# CM4 register map
CPU: CM4 r0p1, selectable endian, MPU, FPU, 4 interrupt priority bits
Registers are 32-bit, read-write, reset 0x0 unless marked. A register's access mark holds for its fields unless they carry their own. Offsets are from the block's base; [hi:lo] are bit positions.

## FP — Floating-Point Extension
Base 0xE000EF34
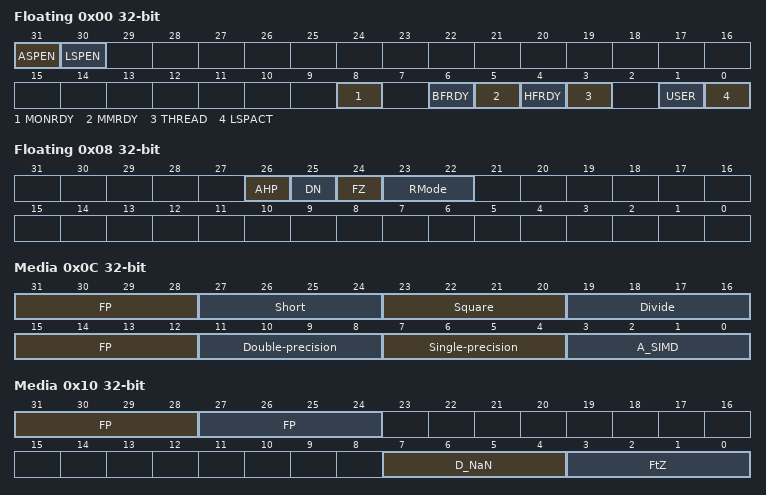
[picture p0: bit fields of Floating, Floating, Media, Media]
0x00 Floating Point Context Control Register — Holds control data for the Floating Point Unit
  [31] ASPEN — When this bit is set to 1, execution of a floating-point instruction sets the CONTROL
    0=Executing an FP instruction has no effect on CONTROL.FPCA; 1=Executing an FP instruction sets CONTROL.FPCA to 1
  [30] LSPEN — Enables lazy context save of FP state
    0=Disable automatic lazy context save; 1=Enable automatic lazy context save
  [8] MONRDY — Indicates whether the software executing when the processor allocated the FP stack frame was able to set the DebugMonitor exception to pending
    0=Not able to set the DebugMonitor exception to pending; 1=Able to set the DebugMonitor exception to pending
  [6] BFRDY — Indicates whether the software executing when the processor allocated the FP stack frame was able to set the BusFault exception to pending
    0=Not able to set the BusFault exception to pending; 1=Able to set the BusFault exception to pending
  [5] MMRDY — Indicates whether the software executing when the processor allocated the FP stack frame was able to set the MemManage exception to pending
    0=Not able to set the MemManage exception to pending; 1=Able to set the MemManage exception to pending
  [4] HFRDY — Indicates whether the software executing when the processor allocated the FP stack frame was able to set the HardFault exception to pending
    0=Not able to set the HardFault exception to pending; 1=Able to set the HardFault exception to pending
  [3] THREAD — Indicates the processor mode when it allocated the FP stack frame
    0=Handler mode; 1=Thread mode
  [1] USER — Indicates the privilege level of the software executing when the processor allocated the FP stack frame
    0=Privileged; 1=Unprivileged
  [0] LSPACT — Indicates whether Lazy preservation of the FP state is active
    0=Lazy state preservation is not active; 1=Lazy state preservation is active
0x04 Floating Point Context Address Register — Holds the location of the unpopulated floating-point register space allocated on an exception stack frame
0x08 Floating Point Default Status Control Register — Holds the default values for the floating-point status control data that the processor assigns to the FPSCR when it creates a new floating-point context
  [26] AHP — Default value for FPSCR.AHP
  [25] DN — Default value for FPSCR.DN
  [24] FZ — Default value for FPSCR.FZ
  [23:22] RMode — Default value for FPSCR.RMode
0x0C Media and FP Feature Register 0 ro — Describes the features provided by the Floating-point extension
  [31:28] FP rounding modes — Indicates the rounding modes supported by the FP floating-point hardware
    1=All rounding modes supported
  [27:24] Short vectors — Indicates the hardware support for FP short vectors
    0=Not supported in ARMv7-M
  [23:20] Square root — Indicates the hardware support for FP square root operations
    1=Supported
  [19:16] Divide — Indicates the hardware support for FP divide operations
    1=Supported
  [15:12] FP exception trapping — Indicates whether the FP hardware implementation supports exception trapping
    0=Not supported in ARMv7-M
  [11:8] Double-precision — Indicates the hardware support for FP double-precision operations
    0=Not supported; 2=Supported
  [7:4] Single-precision — Indicates the hardware support for FP single-precision operations
    2=Supported
  [3:0] A_SIMD registers — Indicates the size of the FP register bank
    1=Supported, 16 x 64-bit registers
0x10 Media and FP Feature Register 1 ro — Describes the features provided by the Floating-point extension
  [31:28] FP fused MAC — Indicates whether the FP supports fused multiply accumulate operations
    1=Supported
  [27:24] FP HPFP — Floating Point Half-Precision and double-precision
    1=Supports conversion between half-precision and single precision; 2=As for 0b0001, and also supports conversion between half-precision and double-precision
  [7:4] D_NaN mode — Indicates whether the FP hardware implementation supports only the Default NaN mode
    1=Hardware supports propagation of NaN values
  [3:0] FtZ mode — Indicates whether the FP hardware implementation supports only the Flush-to-Zero mode of operation
    1=Hardware supports full denormalized number arithmetic
0x14 Media and FP Feature Register 2 ro — Describes the features provided by the floating-point extension
  [7:4] VFP_Misc — Indicates the hardware support for FP miscellaneous features
    0=No support for miscellaneous features; 4=Support for floating-point selection, floating-point conversion to integer with direct rounding modes, floating-point round to i
